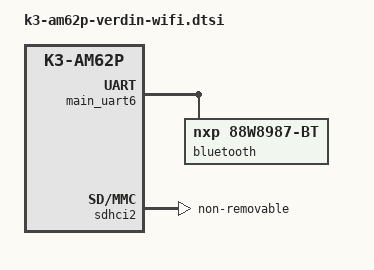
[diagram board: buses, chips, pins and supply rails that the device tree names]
// SPDX-License-Identifier: GPL-2.0-or-later OR MIT
/*
 * Copyright 2025 Toradex
 *
 * Common dtsi for Verdin AM62P SoM WB variant
 *
 * https://www.toradex.com/computer-on-modules/verdin-arm-family/ti-am62p
 */

/* On-module Bluetooth */
&main_uart6 {
	pinctrl-names = "default";
	pinctrl-0 = <&pinctrl_uart6>;
	uart-has-rtscts;
	status = "okay";

	bluetooth {
		compatible = "nxp,88w8987-bt";
		fw-init-baudrate = <3000000>;
	};
};

/* On-module Wi-Fi */
&sdhci2 {
	pinctrl-names = "default";
	pinctrl-0 = <&pinctrl_sdhci2>;
	keep-power-in-suspend;
	non-removable;
	ti,fails-without-test-cd;
	status = "okay";
};
